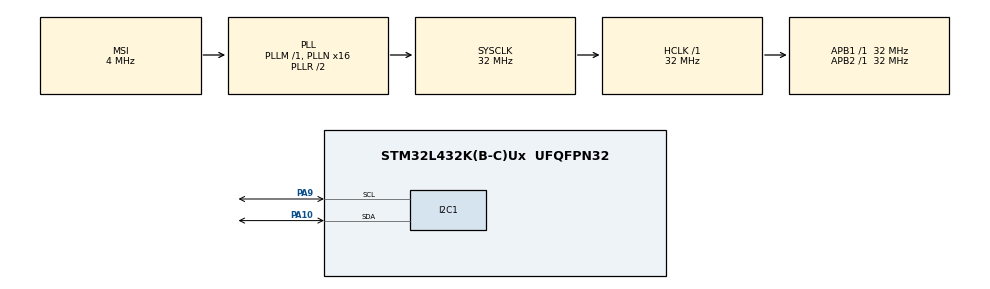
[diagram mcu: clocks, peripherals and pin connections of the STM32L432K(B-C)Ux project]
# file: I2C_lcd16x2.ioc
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I2C1.Timing=0x00707CBB
Mcu.Family=STM32L4
Mcu.Name=STM32L432K(B-C)Ux
Mcu.Package=UFQFPN32
NVIC.PriorityGroup=NVIC_PRIORITYGROUP_4
PA10.Mode=I2C
PA10.Signal=I2C1_SDA
PA13\ (JTMS-SWDIO).Mode=Serial_Wire
PA13\ (JTMS-SWDIO).Signal=SYS_JTMS-SWDIO
PA14\ (JTCK-SWCLK).Mode=Serial_Wire
PA14\ (JTCK-SWCLK).Signal=SYS_JTCK-SWCLK
PA9.Mode=I2C
PA9.Signal=I2C1_SCL
ProjectManager.HeapSize=0x200
ProjectManager.StackSize=0x400
ProjectManager.TargetToolchain=SW4STM32
RCC.AHBFreq_Value=32000000
RCC.APB1Freq_Value=32000000
RCC.APB1TimFreq_Value=32000000
RCC.APB2Freq_Value=32000000
RCC.APB2TimFreq_Value=32000000
RCC.CortexFreq_Value=32000000
RCC.HCLKFreq_Value=32000000
RCC.HSE_VALUE=8000000
RCC.HSI16_VALUE=16000000
RCC.HSI48_VALUE=48000000
RCC.HSI_VALUE=16000000
RCC.LSE_VALUE=32.768
RCC.MSI_VALUE=4000000
RCC.PLLMUL=RCC_PLLMUL_4
RCC.PLLN=16
RCC.SYSCLKFreq_VALUE=32000000
RCC.SYSCLKSource=RCC_SYSCLKSOURCE_PLLCLK
RCC.VCOOutputFreq_Value=64000000
board=NUCLEO-L432KC

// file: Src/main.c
/**
  ******************************************************************************
  * @file           : main.c
  * @brief          : Main program body
  ******************************************************************************
  ** This notice applies to any and all portions of this file
  * that are not between comment pairs USER CODE BEGIN and
  * USER CODE END. Other portions of this file, whether
  * inserted by the user or by software development tools
  * are owned by their respective copyright owners.
  *
  * COPYRIGHT(c) 2018 STMicroelectronics
  *
  * Redistribution and use in source and binary forms, with or without modification,
  * are permitted provided that the following conditions are met:
  *   1. Redistributions of source code must retain the above copyright notice,
  *      this list of conditions and the following disclaimer.
  *   2. Redistributions in binary form must reproduce the above copyright notice,
  *      this list of conditions and the following disclaimer in the documentation
  *      and/or other materials provided with the distribution.
  *   3. Neither the name of STMicroelectronics nor the names of its contributors
  *      may be used to endorse or promote products derived from this software
  *      without specific prior written permission.
  *
  * THIS SOFTWARE IS PROVIDED BY THE COPYRIGHT HOLDERS AND CONTRIBUTORS "AS IS"
  * AND ANY EXPRESS OR IMPLIED WARRANTIES, INCLUDING, BUT NOT LIMITED TO, THE
  * IMPLIED WARRANTIES OF MERCHANTABILITY AND FITNESS FOR A PARTICULAR PURPOSE ARE
  * DISCLAIMED. IN NO EVENT SHALL THE COPYRIGHT HOLDER OR CONTRIBUTORS BE LIABLE
  * FOR ANY DIRECT, INDIRECT, INCIDENTAL, SPECIAL, EXEMPLARY, OR CONSEQUENTIAL
  * DAMAGES (INCLUDING, BUT NOT LIMITED TO, PROCUREMENT OF SUBSTITUTE GOODS OR
  * SERVICES; LOSS OF USE, DATA, OR PROFITS; OR BUSINESS INTERRUPTION) HOWEVER
  * CAUSED AND ON ANY THEORY OF LIABILITY, WHETHER IN CONTRACT, STRICT LIABILITY,
  * OR TORT (INCLUDING NEGLIGENCE OR OTHERWISE) ARISING IN ANY WAY OUT OF THE USE
  * OF THIS SOFTWARE, EVEN IF ADVISED OF THE POSSIBILITY OF SUCH DAMAGE.
  *
  ******************************************************************************
  */
#include "main.h"
#include "stm32l4xx_hal.h"
#include <I2C_lcd16x2.h>

I2C_HandleTypeDef hi2c1;

/* USER CODE BEGIN PV */
/* Private variables ---------------------------------------------------------*/

/* USER CODE END PV */

void SystemClock_Config(void);
static void MX_GPIO_Init(void);
static void MX_I2C1_Init(void);

/* USER CODE BEGIN PFP */
/* Private function prototypes -----------------------------------------------*/

/* USER CODE END PFP */

int main(void)
{

  /* MCU Configuration----------------------------------------------------------*/

  /* Reset of all peripherals, Initializes the Flash interface and the Systick. */
  HAL_Init();

  /* Configure the system clock */
  SystemClock_Config();

  /* Initialize all configured peripherals */
  MX_GPIO_Init();
  MX_I2C1_Init();
  /* USER CODE BEGIN 2 */

  LCD1602_i2c_Init();
  LCD1602_noCursor();
  LCD1602_noBlink();
  //Use UTF-8 to correct see the characters in your IDE
  LCD1602_special_character_Init("ç", "á", "ú", "é", "í", "ã","õ","ô");
  LCD1602_print("Atenção");

  /* USER CODE END 2 */

  /* Infinite loop */
  while (1)
  {

  }

}

void SystemClock_Config(void)
{

  RCC_OscInitTypeDef RCC_OscInitStruct;
  RCC_ClkInitTypeDef RCC_ClkInitStruct;
  RCC_PeriphCLKInitTypeDef PeriphClkInit;

    /**Initializes the CPU, AHB and APB busses clocks
    */
  RCC_OscInitStruct.OscillatorType = RCC_OSCILLATORTYPE_MSI;
  RCC_OscInitStruct.MSIState = RCC_MSI_ON;
  RCC_OscInitStruct.MSICalibrationValue = 0;
  RCC_OscInitStruct.MSIClockRange = RCC_MSIRANGE_6;
  RCC_OscInitStruct.PLL.PLLState = RCC_PLL_ON;
  RCC_OscInitStruct.PLL.PLLSource = RCC_PLLSOURCE_MSI;
  RCC_OscInitStruct.PLL.PLLM = 1;
  RCC_OscInitStruct.PLL.PLLN = 16;
  RCC_OscInitStruct.PLL.PLLP = RCC_PLLP_DIV7;
  RCC_OscInitStruct.PLL.PLLQ = RCC_PLLQ_DIV2;
  RCC_OscInitStruct.PLL.PLLR = RCC_PLLR_DIV2;
  if (HAL_RCC_OscConfig(&RCC_OscInitStruct) != HAL_OK)
  {
    _Error_Handler(__FILE__, __LINE__);
  }

    /**Initializes the CPU, AHB and APB busses clocks
    */
  RCC_ClkInitStruct.ClockType = RCC_CLOCKTYPE_HCLK|RCC_CLOCKTYPE_SYSCLK
                              |RCC_CLOCKTYPE_PCLK1|RCC_CLOCKTYPE_PCLK2;
  RCC_ClkInitStruct.SYSCLKSource = RCC_SYSCLKSOURCE_PLLCLK;
  RCC_ClkInitStruct.AHBCLKDivider = RCC_SYSCLK_DIV1;
  RCC_ClkInitStruct.APB1CLKDivider = RCC_HCLK_DIV1;
  RCC_ClkInitStruct.APB2CLKDivider = RCC_HCLK_DIV1;

  if (HAL_RCC_ClockConfig(&RCC_ClkInitStruct, FLASH_LATENCY_1) != HAL_OK)
  {
    _Error_Handler(__FILE__, __LINE__);
  }

  PeriphClkInit.PeriphClockSelection = RCC_PERIPHCLK_I2C1;
  PeriphClkInit.I2c1ClockSelection = RCC_I2C1CLKSOURCE_PCLK1;
  if (HAL_RCCEx_PeriphCLKConfig(&PeriphClkInit) != HAL_OK)
  {
    _Error_Handler(__FILE__, __LINE__);
  }

    /**Configure the main internal regulator output voltage
    */
  if (HAL_PWREx_ControlVoltageScaling(PWR_REGULATOR_VOLTAGE_SCALE1) != HAL_OK)
  {
    _Error_Handler(__FILE__, __LINE__);
  }

    /**Configure the Systick interrupt time
    */
  HAL_SYSTICK_Config(HAL_RCC_GetHCLKFreq()/1000);

    /**Configure the Systick
    */
  HAL_SYSTICK_CLKSourceConfig(SYSTICK_CLKSOURCE_HCLK);

  /* SysTick_IRQn interrupt configuration */
  HAL_NVIC_SetPriority(SysTick_IRQn, 0, 0);
}

/* I2C1 init function */
static void MX_I2C1_Init(void)
{

  hi2c1.Instance = I2C1;
  hi2c1.Init.Timing = 0x00707CBB;
  hi2c1.Init.OwnAddress1 = 0;
  hi2c1.Init.AddressingMode = I2C_ADDRESSINGMODE_7BIT;
  hi2c1.Init.DualAddressMode = I2C_DUALADDRESS_DISABLE;
  hi2c1.Init.OwnAddress2 = 0;
  hi2c1.Init.OwnAddress2Masks = I2C_OA2_NOMASK;
  hi2c1.Init.GeneralCallMode = I2C_GENERALCALL_DISABLE;
  hi2c1.Init.NoStretchMode = I2C_NOSTRETCH_DISABLE;
  if (HAL_I2C_Init(&hi2c1) != HAL_OK)
  {
    _Error_Handler(__FILE__, __LINE__);
  }

    /**Configure Analogue filter
    */
  if (HAL_I2CEx_ConfigAnalogFilter(&hi2c1, I2C_ANALOGFILTER_ENABLE) != HAL_OK)
  {
    _Error_Handler(__FILE__, __LINE__);
  }

    /**Configure Digital filter
    */
  if (HAL_I2CEx_ConfigDigitalFilter(&hi2c1, 0) != HAL_OK)
  {
    _Error_Handler(__FILE__, __LINE__);
  }

}

/** Configure pins as
        * Analog
        * Input
        * Output
        * EVENT_OUT
        * EXTI
        * Free pins are configured automatically as Analog (this feature is enabled through
        * the Code Generation settings)
*/
static void MX_GPIO_Init(void)
{

  GPIO_InitTypeDef GPIO_InitStruct;

  /* GPIO Ports Clock Enable */
  __HAL_RCC_GPIOC_CLK_ENABLE();
  __HAL_RCC_GPIOA_CLK_ENABLE();
  __HAL_RCC_GPIOB_CLK_ENABLE();
  __HAL_RCC_GPIOH_CLK_ENABLE();

  /*Configure GPIO pins : PC14 PC15 */
  GPIO_InitStruct.Pin = GPIO_PIN_14|GPIO_PIN_15;
  GPIO_InitStruct.Mode = GPIO_MODE_ANALOG;
  GPIO_InitStruct.Pull = GPIO_NOPULL;
  HAL_GPIO_Init(GPIOC, &GPIO_InitStruct);

  /*Configure GPIO pins : PA0 PA1 PA2 PA3
                           PA4 PA5 PA6 PA7
                           PA8 PA11 PA12 PA15 */
  GPIO_InitStruct.Pin = GPIO_PIN_0|GPIO_PIN_1|GPIO_PIN_2|GPIO_PIN_3
                          |GPIO_PIN_4|GPIO_PIN_5|GPIO_PIN_6|GPIO_PIN_7
                          |GPIO_PIN_8|GPIO_PIN_11|GPIO_PIN_12|GPIO_PIN_15;
  GPIO_InitStruct.Mode = GPIO_MODE_ANALOG;
  GPIO_InitStruct.Pull = GPIO_NOPULL;
  HAL_GPIO_Init(GPIOA, &GPIO_InitStruct);

  /*Configure GPIO pins : PB0 PB1 PB3 PB4
                           PB5 PB6 PB7 */
  GPIO_InitStruct.Pin = GPIO_PIN_0|GPIO_PIN_1|GPIO_PIN_3|GPIO_PIN_4
                          |GPIO_PIN_5|GPIO_PIN_6|GPIO_PIN_7;
  GPIO_InitStruct.Mode = GPIO_MODE_ANALOG;
  GPIO_InitStruct.Pull = GPIO_NOPULL;
  HAL_GPIO_Init(GPIOB, &GPIO_InitStruct);

  /*Configure GPIO pin : PH3 */
  GPIO_InitStruct.Pin = GPIO_PIN_3;
  GPIO_InitStruct.Mode = GPIO_MODE_ANALOG;
  GPIO_InitStruct.Pull = GPIO_NOPULL;
  HAL_GPIO_Init(GPIOH, &GPIO_InitStruct);

}

void _Error_Handler(char *file, int line)
{
  while(1)
  {
  }
}

/************************ (C) COPYRIGHT STMicroelectronics *****END OF FILE****/
